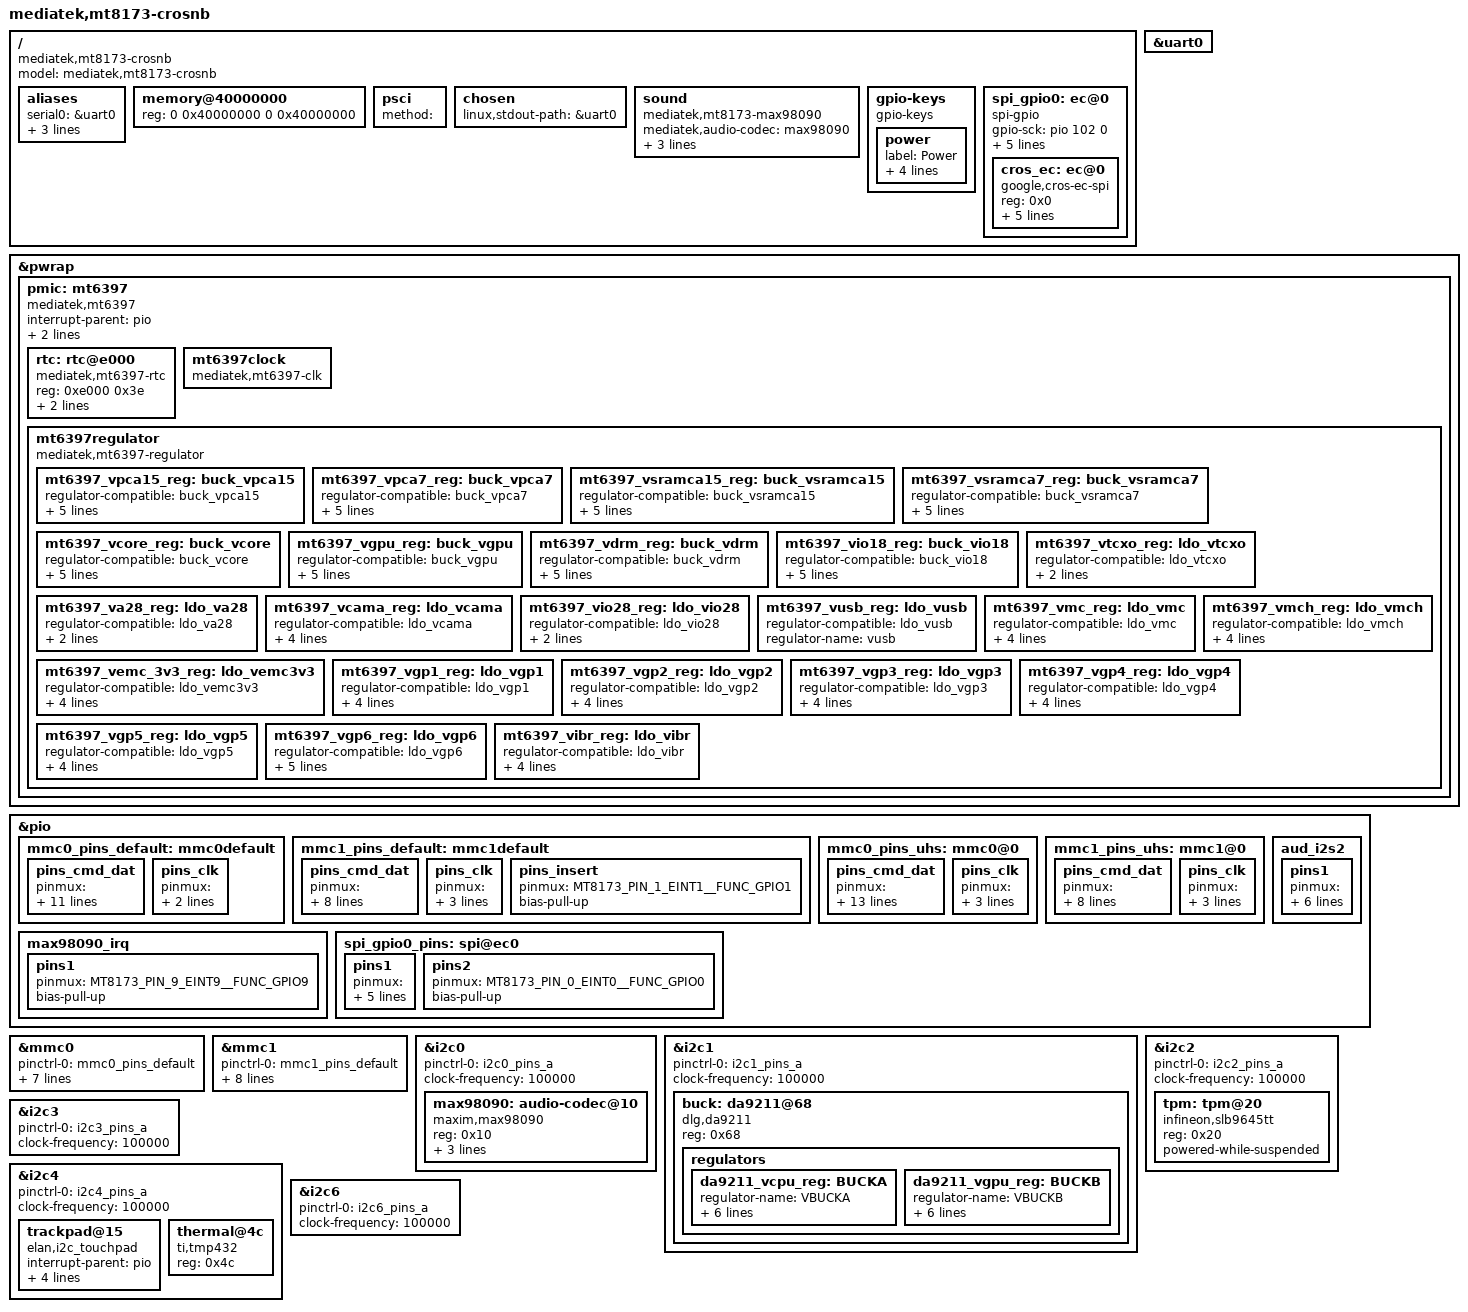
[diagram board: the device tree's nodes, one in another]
/*
 * Copyright (c) 2014 MediaTek Inc.
 * Author: Eddie Huang <eddie.huang@mediatek.com>
 *
 * This program is free software; you can redistribute it and/or modify
 * it under the terms of the GNU General Public License version 2 as
 * published by the Free Software Foundation.
 *
 * This program is distributed in the hope that it will be useful,
 * but WITHOUT ANY WARRANTY; without even the implied warranty of
 * MERCHANTABILITY or FITNESS FOR A PARTICULAR PURPOSE.  See the
 * GNU General Public License for more details.
 */

/dts-v1/;
#include <dt-bindings/input/input.h>
#include <dt-bindings/gpio/gpio.h>
#include <dt-bindings/clock/mediatek,mt6397-clks.h>
#include "mt8173.dtsi"

/ {
	model = "mediatek,mt8173-crosnb";
	compatible = "mediatek,mt8173-crosnb", "mediatek,mt8173";

	aliases {
		serial0 = &uart0;
		serial1 = &uart1;
		serial2 = &uart2;
		serial3 = &uart3;
	};

	memory@40000000 {
		device_type = "memory";
		reg = <0 0x40000000 0 0x40000000>;
	};

	psci {
		method = "";
        };

	chosen {
		linux,stdout-path = &uart0;
	};

	sound {
		compatible = "mediatek,mt8173-max98090";
		mediatek,audio-codec = <&max98090>;
		reg-vgp1-supply = <&mt6397_vgp1_reg>;
		reg-vgp4-supply = <&mt6397_vgp4_reg>;
		pinctrl-names = "default";
		pinctrl-0 = <&aud_i2s2>;
		status = "okay";
	};

	gpio-keys {
		compatible = "gpio-keys";
		power {
			label = "Power";
			gpios = <&pio 14 GPIO_ACTIVE_HIGH>;
			linux,code = <KEY_POWER>;
			debounce-interval = <1>;
			gpio-key,wakeup;
		};
	};

	spi_gpio0: ec@0 {
		compatible = "spi-gpio";
		#address-cells = <0x1>;
		#size-cells = <0>;
		gpio-sck = <&pio 102 0>;
		gpio-miso = <&pio 103 0>;
		gpio-mosi = <&pio 104 0>;
		cs-gpios = <&pio 105 0>;
		num-chipselects = <1>;
	};
};

&uart0 {
	status = "okay";
};

&pwrap {
	pmic: mt6397 {
		compatible = "mediatek,mt6397";
		#address-cells = <1>;
		#size-cells = <1>;
		interrupt-parent = <&pio>;
		interrupts = <5 IRQ_TYPE_LEVEL_HIGH>;
		interrupt-controller;
		#interrupt-cells = <2>;

		rtc: rtc@e000 {
			compatible = "mediatek,mt6397-rtc";
			reg = <0xe000 0x3e>;
			interrupt-parent = <&pmic>;
			interrupts = <20 IRQ_TYPE_LEVEL_HIGH>;
		};

		mt6397clock: mt6397clock {
			compatible = "mediatek,mt6397-clk";
			#clock-cells = <1>;
		};

		mt6397regulator: mt6397regulator {
			compatible = "mediatek,mt6397-regulator";

			mt6397_vpca15_reg: buck_vpca15 {
				regulator-compatible = "buck_vpca15";
				regulator-name = "vpca15";
				regulator-min-microvolt = < 700000>;
				regulator-max-microvolt = <1350000>;
				regulator-ramp-delay = <12500>;
				regulator-always-on;
			};

			mt6397_vpca7_reg: buck_vpca7 {
				regulator-compatible = "buck_vpca7";
				regulator-name = "vpca7";
				regulator-min-microvolt = < 700000>;
				regulator-max-microvolt = <1350000>;
				regulator-ramp-delay = <12500>;
				regulator-enable-ramp-delay = <115>;
			};

			mt6397_vsramca15_reg: buck_vsramca15 {
				regulator-compatible = "buck_vsramca15";
				regulator-name = "vsramca15";
				regulator-min-microvolt = < 700000>;
				regulator-max-microvolt = <1350000>;
				regulator-ramp-delay = <12500>;
				regulator-always-on;
			};

			mt6397_vsramca7_reg: buck_vsramca7 {
				regulator-compatible = "buck_vsramca7";
				regulator-name = "vsramca7";
				regulator-min-microvolt = < 700000>;
				regulator-max-microvolt = <1350000>;
				regulator-ramp-delay = <12500>;
				regulator-always-on;
			};

			mt6397_vcore_reg: buck_vcore {
				regulator-compatible = "buck_vcore";
				regulator-name = "vcore";
				regulator-min-microvolt = < 700000>;
				regulator-max-microvolt = <1350000>;
				regulator-ramp-delay = <12500>;
				regulator-always-on;
			};

			mt6397_vgpu_reg: buck_vgpu {
				regulator-compatible = "buck_vgpu";
				regulator-name = "vgpu";
				regulator-min-microvolt = < 700000>;
				regulator-max-microvolt = <1350000>;
				regulator-ramp-delay = <12500>;
				regulator-enable-ramp-delay = <115>;
			};

			mt6397_vdrm_reg: buck_vdrm {
				regulator-compatible = "buck_vdrm";
				regulator-name = "vdrm";
				regulator-min-microvolt = <1200000>;
				regulator-max-microvolt = <1400000>;
				regulator-ramp-delay = <12500>;
				regulator-always-on;
			};

			mt6397_vio18_reg: buck_vio18 {
				regulator-compatible = "buck_vio18";
				regulator-name = "vio18";
				regulator-min-microvolt = <1620000>;
				regulator-max-microvolt = <1980000>;
				regulator-ramp-delay = <12500>;
				regulator-always-on;
			};

			mt6397_vtcxo_reg: ldo_vtcxo {
				regulator-compatible = "ldo_vtcxo";
				regulator-name = "vtcxo";
				regulator-always-on;
			};

			mt6397_va28_reg: ldo_va28 {
				regulator-compatible = "ldo_va28";
				regulator-name = "va28";
				regulator-always-on;
			};

			mt6397_vcama_reg: ldo_vcama {
				regulator-compatible = "ldo_vcama";
				regulator-name = "vcama";
				regulator-min-microvolt = <1500000>;
				regulator-max-microvolt = <2800000>;
				regulator-enable-ramp-delay = <218>;
			};

			mt6397_vio28_reg: ldo_vio28 {
				regulator-compatible = "ldo_vio28";
				regulator-name = "vio28";
				regulator-always-on;
			};

			mt6397_vusb_reg: ldo_vusb {
				regulator-compatible = "ldo_vusb";
				regulator-name = "vusb";
			};

			mt6397_vmc_reg: ldo_vmc {
				regulator-compatible = "ldo_vmc";
				regulator-name = "vmc";
				regulator-min-microvolt = <1800000>;
				regulator-max-microvolt = <3300000>;
				regulator-enable-ramp-delay = <218>;
			};

			mt6397_vmch_reg: ldo_vmch {
				regulator-compatible = "ldo_vmch";
				regulator-name = "vmch";
				regulator-min-microvolt = <3000000>;
				regulator-max-microvolt = <3300000>;
				regulator-enable-ramp-delay = <218>;
			};

			mt6397_vemc_3v3_reg: ldo_vemc3v3 {
				regulator-compatible = "ldo_vemc3v3";
				regulator-name = "vemc_3v3";
				regulator-min-microvolt = <3000000>;
				regulator-max-microvolt = <3300000>;
				regulator-enable-ramp-delay = <218>;
			};

			mt6397_vgp1_reg: ldo_vgp1 {
				regulator-compatible = "ldo_vgp1";
				regulator-name = "vcamd";
				regulator-min-microvolt = <1220000>;
				regulator-max-microvolt = <3300000>;
				regulator-enable-ramp-delay = <240>;
			};

			mt6397_vgp2_reg: ldo_vgp2 {
				regulator-compatible = "ldo_vgp2";
				regulator-name = "vcamio";
				regulator-min-microvolt = <1000000>;
				regulator-max-microvolt = <3300000>;
				regulator-enable-ramp-delay = <218>;
			};

			mt6397_vgp3_reg: ldo_vgp3 {
				regulator-compatible = "ldo_vgp3";
				regulator-name = "vcamaf";
				regulator-min-microvolt = <1200000>;
				regulator-max-microvolt = <3300000>;
				regulator-enable-ramp-delay = <218>;
			};

			mt6397_vgp4_reg: ldo_vgp4 {
				regulator-compatible = "ldo_vgp4";
				regulator-name = "vgp4";
				regulator-min-microvolt = <1200000>;
				regulator-max-microvolt = <3300000>;
				regulator-enable-ramp-delay = <218>;
			};

			mt6397_vgp5_reg: ldo_vgp5 {
				regulator-compatible = "ldo_vgp5";
				regulator-name = "vgp5";
				regulator-min-microvolt = <1200000>;
				regulator-max-microvolt = <3000000>;
				regulator-enable-ramp-delay = <218>;
			};

			mt6397_vgp6_reg: ldo_vgp6 {
				regulator-compatible = "ldo_vgp6";
				regulator-name = "vgp6";
				regulator-min-microvolt = <3300000>;
				regulator-max-microvolt = <3300000>;
				regulator-enable-ramp-delay = <218>;
				regulator-always-on;
			};

			mt6397_vibr_reg: ldo_vibr {
				regulator-compatible = "ldo_vibr";
				regulator-name = "vibr";
				regulator-min-microvolt = <1300000>;
				regulator-max-microvolt = <3300000>;
				regulator-enable-ramp-delay = <218>;
			};
		};
	};
};

&pio {
	mmc0_pins_default: mmc0default {
		pins_cmd_dat {
			pinmux = <MT8173_PIN_64_MSDC0_DAT7__FUNC_MSDC0_DAT7>,
				<MT8173_PIN_63_MSDC0_DAT6__FUNC_MSDC0_DAT6>,
				<MT8173_PIN_62_MSDC0_DAT5__FUNC_MSDC0_DAT5>,
				<MT8173_PIN_61_MSDC0_DAT4__FUNC_MSDC0_DAT4>,
				<MT8173_PIN_66_MSDC0_CMD__FUNC_MSDC0_CMD>,
				<MT8173_PIN_60_MSDC0_DAT3__FUNC_MSDC0_DAT3>,
				<MT8173_PIN_59_MSDC0_DAT2__FUNC_MSDC0_DAT2>,
				<MT8173_PIN_58_MSDC0_DAT1__FUNC_MSDC0_DAT1>,
				<MT8173_PIN_57_MSDC0_DAT0__FUNC_MSDC0_DAT0>,
				<MT8173_PIN_68_MSDC0_RST___FUNC_MSDC0_RSTB>;
				bias-pull-up;
		};
		pins_clk {
			pinmux =  <MT8173_PIN_65_MSDC0_CLK__FUNC_MSDC0_CLK>;
				bias-pull-down;
		};
	};

	mmc1_pins_default: mmc1default {
		pins_cmd_dat {
			pinmux = <MT8173_PIN_73_MSDC1_DAT0__FUNC_MSDC1_DAT0>,
			     <MT8173_PIN_74_MSDC1_DAT1__FUNC_MSDC1_DAT1>,
			     <MT8173_PIN_78_MSDC1_CMD__FUNC_MSDC1_CMD>,
			     <MT8173_PIN_75_MSDC1_DAT2__FUNC_MSDC1_DAT2>,
			     <MT8173_PIN_76_MSDC1_DAT3__FUNC_MSDC1_DAT3>;
			input-enable;
			drive-strength = <MTK_DRIVE_4mA>;
			bias-pull-up = <MTK_PUPD_SET_R1R0_10>;
		};

		pins_clk {
			pinmux = <MT8173_PIN_77_MSDC1_CLK__FUNC_MSDC1_CLK>;
			bias-pull-down;
			drive-strength = <MTK_DRIVE_4mA>;
		};

		pins_insert {
			pinmux = <MT8173_PIN_1_EINT1__FUNC_GPIO1>;
			bias-pull-up;
		};
	};

	mmc0_pins_uhs: mmc0@0{
		pins_cmd_dat {
			pinmux = <MT8173_PIN_64_MSDC0_DAT7__FUNC_MSDC0_DAT7>,
			     <MT8173_PIN_63_MSDC0_DAT6__FUNC_MSDC0_DAT6>,
			     <MT8173_PIN_62_MSDC0_DAT5__FUNC_MSDC0_DAT5>,
			     <MT8173_PIN_61_MSDC0_DAT4__FUNC_MSDC0_DAT4>,
			     <MT8173_PIN_66_MSDC0_CMD__FUNC_MSDC0_CMD>,
			     <MT8173_PIN_60_MSDC0_DAT3__FUNC_MSDC0_DAT3>,
			     <MT8173_PIN_59_MSDC0_DAT2__FUNC_MSDC0_DAT2>,
			     <MT8173_PIN_58_MSDC0_DAT1__FUNC_MSDC0_DAT1>,
			     <MT8173_PIN_57_MSDC0_DAT0__FUNC_MSDC0_DAT0>,
			     <MT8173_PIN_68_MSDC0_RST___FUNC_MSDC0_RSTB>;
			input-enable;
			drive-strength = <MTK_DRIVE_2mA>;
			bias-pull-up = <MTK_PUPD_SET_R1R0_01>;
		};

		pins_clk {
			pinmux = <MT8173_PIN_65_MSDC0_CLK__FUNC_MSDC0_CLK>;
			drive-strength = <MTK_DRIVE_2mA>;
			bias-pull-down = <MTK_PUPD_SET_R1R0_01>;
		};
	};

	mmc1_pins_uhs: mmc1@0 {
		pins_cmd_dat {
			pinmux = <MT8173_PIN_73_MSDC1_DAT0__FUNC_MSDC1_DAT0>,
			     <MT8173_PIN_74_MSDC1_DAT1__FUNC_MSDC1_DAT1>,
			     <MT8173_PIN_78_MSDC1_CMD__FUNC_MSDC1_CMD>,
			     <MT8173_PIN_75_MSDC1_DAT2__FUNC_MSDC1_DAT2>,
			     <MT8173_PIN_76_MSDC1_DAT3__FUNC_MSDC1_DAT3>;
			input-enable;
			drive-strength = <MTK_DRIVE_4mA>;
			bias-pull-up = <MTK_PUPD_SET_R1R0_10>;
		};

		pins_clk {
			pinmux = <MT8173_PIN_77_MSDC1_CLK__FUNC_MSDC1_CLK>;
			drive-strength = <MTK_DRIVE_4mA>;
			bias-pull-down = <MTK_PUPD_SET_R1R0_10>;
		};
	};
};

&mmc0 {
	pinctrl-names = "default", "state_uhs";
	pinctrl-0 = <&mmc0_pins_default>;
	pinctrl-1 = <&mmc0_pins_uhs>;
	status = "okay";
	bus-width = <8>;
	max-frequency = <50000000>;
	cap-mmc-highspeed;
	core-power-supply = <&mt6397_vemc_3v3_reg>;
	non-removable;
	func = "EMMC";
};

&mmc1 {
	pinctrl-names = "default", "state_uhs";
	pinctrl-0 = <&mmc1_pins_default>;
	pinctrl-1 = <&mmc1_pins_uhs>;
	status = "okay";
	bus-width = <4>;
	max-frequency = <25000000>;
	cap-sd-highspeed;
	cd-gpios = <&pio 1 0>;
	core-power-supply = <&mt6397_vmch_reg>;
	io-power-supply = <&mt6397_vmc_reg>;
	func = "SDCARD";
};

&i2c0 {
	pinctrl-names = "default";
	pinctrl-0 = <&i2c0_pins_a>;
	status = "okay";
	clock-frequency = <100000>;
	#address-cells = <1>;
	#size-cells = <0>;
	max98090: audio-codec@10 {
		compatible = "maxim,max98090";
		reg = <0x10>;
		interrupt-parent = <&pio>;
		interrupts = <9 IRQ_TYPE_EDGE_FALLING>;
		pinctrl-names = "default";
		pinctrl-0 = <&max98090_irq>;
	};
};

&i2c1 {
	pinctrl-names = "default";
	pinctrl-0 = <&i2c1_pins_a>;
	status = "okay";
	clock-frequency = <100000>;
	#address-cells = <1>;
	#size-cells = <0>;
	buck: da9211@68 {
		compatible = "dlg,da9211";
		reg = <0x68>;
		regulators {
			da9211_vcpu_reg: BUCKA {
				regulator-name = "VBUCKA";
				regulator-min-microvolt = < 700000>;
				regulator-max-microvolt = <1310000>;
				regulator-min-microamp 	= <2000000>;
				regulator-max-microamp 	= <4400000>;
				regulator-ramp-delay = <10000>;
				regulator-always-on;
			};
			da9211_vgpu_reg: BUCKB {
				regulator-name = "VBUCKB";
				regulator-min-microvolt = < 700000>;
				regulator-max-microvolt = <1310000>;
				regulator-min-microamp 	= <2000000>;
				regulator-max-microamp 	= <3000000>;
				regulator-ramp-delay = <10000>;
				regulator-always-on;
			};
		};
	};
};

&i2c2 {
	pinctrl-names = "default";
	pinctrl-0 = <&i2c2_pins_a>;
	status = "okay";
	clock-frequency = <100000>;
	tpm: tpm@20 {
		compatible = "infineon,slb9645tt";
		reg = <0x20>;
		powered-while-suspended;
	};
};

&i2c3 {
	pinctrl-names = "default";
	pinctrl-0 = <&i2c3_pins_a>;
	status = "okay";
	clock-frequency = <100000>;
};

&i2c4 {
	pinctrl-names = "default";
	pinctrl-0 = <&i2c4_pins_a>;
	status = "okay";
	clock-frequency = <100000>;
	#address-cells = <0x1>;
	#size-cells = <0>;
	trackpad@15 {
		compatible = "elan,i2c_touchpad";
		interrupt-parent = <&pio>;
		interrupts = <7 IRQ_TYPE_LEVEL_LOW>;
		reg = <0x15>;
		vcc-supply = <&mt6397_vgp6_reg>;
		wakeup-source;
	};
	thermal@4c {
		compatible = "ti,tmp432";
		reg = <0x4c>;
	};
};

&i2c6 {
	pinctrl-names = "default";
	pinctrl-0 = <&i2c6_pins_a>;
	status = "okay";
	clock-frequency = <100000>;
};

&pio {
	aud_i2s2: aud_i2s2 {
		pins1 {
			pinmux = <MT8173_PIN_128_I2S0_LRCK__FUNC_I2S0_WS>,
					<MT8173_PIN_129_I2S0_BCK__FUNC_I2S0_BCK>,
					<MT8173_PIN_130_I2S0_MCK__FUNC_I2S0_MCK>,
					<MT8173_PIN_131_I2S0_DATA0__FUNC_I2S0_DO>,
					<MT8173_PIN_132_I2S0_DATA1__FUNC_I2S0_DI>;
			bias-pull-down;
		};
	};
	max98090_irq: max98090_irq {
		pins1 {
			pinmux = <MT8173_PIN_9_EINT9__FUNC_GPIO9>;
			bias-pull-up;
		};
	};

	spi_gpio0_pins: spi@ec0 {
		pins1 {
			pinmux = <MT8173_PIN_102_MSDC2_DAT2__FUNC_GPIO102>,
				<MT8173_PIN_103_MSDC2_DAT3__FUNC_GPIO103>,
				<MT8173_PIN_104_MSDC2_CLK__FUNC_GPIO104>,
				<MT8173_PIN_105_MSDC2_CMD__FUNC_GPIO105>;
			bias-disable;
		};

		pins2 {
			pinmux = <MT8173_PIN_0_EINT0__FUNC_GPIO0>;
			bias-pull-up;
		};
	};

};

&spi_gpio0 {
        pinctrl-names = "default";
        pinctrl-0 = <&spi_gpio0_pins>;
        status = "okay";
	/* clients */
	cros_ec: ec@0 {
		compatible = "google,cros-ec-spi";
		reg = <0x0>;
		spi-max-frequency = <18000000>;
		interrupt-parent = <&pio>;
		interrupts = <0 IRQ_TYPE_LEVEL_LOW>;
		google,cros-ec-spi-msg-delay = <500>;
		google,cros-ec-spi-pre-delay = <500>;
	};
};

#include "mt8173-cros-ec-keyboard.dtsi"
